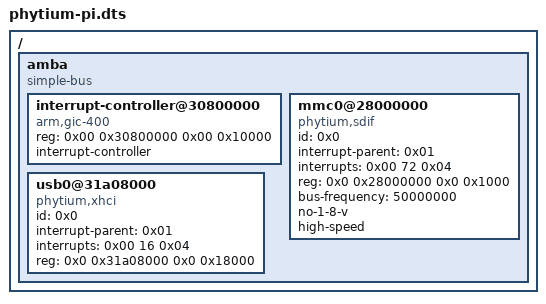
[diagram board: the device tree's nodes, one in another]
/* SPDX-License-Identifier: BSD-2-Clause */

/dts-v1/;

/ {
	#address-cells = <0x02>;
	#size-cells = <0x02>;

	amba {
		compatible = "simple-bus";
		#address-cells = <0x02>;
		#size-cells = <0x02>;
		ranges;

		interrupt-controller@30800000 {
			compatible = "arm,gic-400";
			#address-cells = <0x02>;
			#interrupt-cells = <0x03>;
			reg = <0x00 0x30800000 0x00 0x10000>;
			interrupt-controller;
			phandle = <0x01>;
		};

		mmc0@28000000 {
			id = <0x0>;
			compatible = "phytium,sdif";
			status = "okay";
			interrupt-parent = <0x01>;
			interrupts = <0x00 72 0x04>;
			reg = <0x0 0x28000000 0x0 0x1000>;
			bus-frequency = <50000000>;
			no-1-8-v;
			high-speed;
		};

		usb0@31a08000 {
			id = <0x0>;
			compatible = "phytium,xhci";
			status = "okay";
			interrupt-parent = <0x01>;
			/* spi int-id: (48 - 32)  */
			interrupts = <0x00 16 0x04>;
			reg = <0x0 0x31a08000 0x0 0x18000>;
		};
	};
};
